# R7FA4C1BD register map
Vendor: Renesas Electronics Corporation; Series: RA4; File version: 1.10.00
CPU: CM33 r0p4, little endian, MPU, FPU, VTOR, 4 interrupt priority bits, 96 interrupts
Registers are 32-bit, read-write, reset 0x0 unless marked. A register's access mark holds for its fields unless they carry their own. Offsets are from the block's base; [hi:lo] are bit positions; <NAME> marks a mode.

## IIC0WU — IIC0 Wake-up Unit
Base 0x4009F014
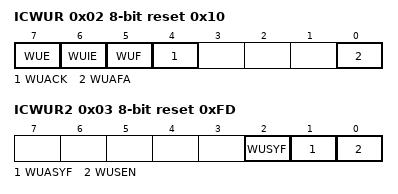
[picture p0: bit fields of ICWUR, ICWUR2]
0x02 ICWUR 8-bit reset 0x10 — I2C Bus Wakeup Unit Register
  [7] WUE — Wakeup Function Enable
    0=Disable wakeup function; 1=Enable wakeup function
  [6] WUIE — Wakeup Interrupt Request Enable
    0=Disable wakeup interrupt request (IIC0_WUI); 1=Enable wakeup interrupt request (IIC0_WUI)
  [5] WUF — Wakeup Event Occurrence Flag
    0=Slave address not matching during wakeup; 1=Slave address matching during wakeup
  [4] WUACK — ACK Bit for Wakeup Mode
  [0] WUAFA — Wakeup Analog Filter Additional Selection
    0=Do not add the wakeup analog filter; 1=Add the wakeup analog filter
0x03 ICWUR2 8-bit reset 0xFD — I2C Bus Wakeup Unit Register 2
  [2] WUSYF ro — Wakeup Function Synchronous Operation Status Flag
    0=IIC asynchronous circuit enable condition; 1=IIC synchronous circuit enable condition
  [1] WUASYF ro — Wakeup Function Asynchronous Operation Status Flag
    0=IIC synchronous circuit enable condition; 1=IIC asynchronous circuit enable condition
  [0] WUSEN — Wakeup Function Synchronous Enable
    0=IIC asynchronous circuit enable; 1=IIC synchronous circuit enable

## CRC — Cyclic Redundancy Check Calculator
Base 0x40108000
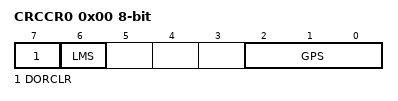
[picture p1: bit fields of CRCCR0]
0x00 CRCCR0 8-bit — CRC Control Register 0
  [7] DORCLR wo — CRCDOR/CRCDOR_HA/CRCDOR_BY Register Clear
    0=No effect; 1=Clear the CRCDOR/CRCDOR_HA/CRCDOR_BY register
  [6] LMS — CRC Calculation Switching
    0=Generate CRC code for LSB-first communication; 1=Generate CRC code for MSB-first communication
  [2:0] GPS — CRC Generating Polynomial Switching
    1=8-bit CRC-8 (X8 + X2 + X + 1); 2=16-bit CRC-16 (X16 + X15 + X2 + 1); 3=16-bit CRC-CCITT (X16 + X12 + X5 + 1); 4=32-bit CRC-32 (X32 + X26 + X23 + X22 + X16 + X12 + X11 +X10 + X8 + X7 + X5 + X4 + X2 + X + 1); 5=32-bit CRC-32C (X32 + X28 + X27 + X26 + X25 + X23 + X22 + X20 + X19 + X18 + X14 + X13 + X11 + X10 + X9 + X8 + X6 + 1); other=Others (No calculation is executed)
0x04 CRCDIR — CRC Data Input Register
0x04 CRCDIR_BY 8-bit (alternate view of CRCDIR) — CRC Data Input Register
0x08 CRCDOR — CRC Data Output Register
0x08 CRCDOR_HA 16-bit (alternate view of CRCDOR) — CRC Data Output Register
0x08 CRCDOR_BY 8-bit (alternate view of CRCDOR) — CRC Data Output Register

## DOC_B — Data Operation Circuit
Base 0x40109000
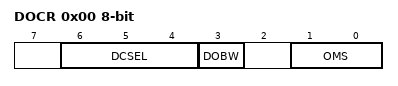
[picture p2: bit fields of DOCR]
0x00 DOCR 8-bit — DOC Control Register
  [6:4] DCSEL — Detection Condition Select
    0=Mismatch (DODSR0 ≠ DODIR); 1=Match (DODSR0 = DODIR); 2=Lower (DODSR0 > DODIR); 3=Upper (DODSR0 < DODIR); 4=Inside window (DODSR0 < DODIR < DODSR1); 5=Outside window (DODIR < DODSR0, DODSR1 < DODIR); other=Others (Setting prohibited)
  [3] DOBW — Data Operation Bit Width Select
    0=16-bit; 1=32-bit
  [1:0] OMS — Operating Mode Select
    0=Data comparison mode; 1=Data addition mode; 2=Data subtraction mode; 3=Setting prohibited
0x04 DOSR 8-bit ro — DOC Flag Status Register
  [0] DOPCF — Data Operation Circuit Flag
0x08 DOSCR 8-bit wo — DOC Flag Status Clear Register
  [0] DOPCFCL — DOPCF Clear
    0=Maintains the DOPCF flag state; 1=Clears the DOPCF flag
0x0C DODIR — DOC Data Input Register
0x10 DODSR0 — DOC Data Setting Register 0
0x14 DODSR1 — DOC Data Setting Register 1

## ECCMB
Base 0x4012F000
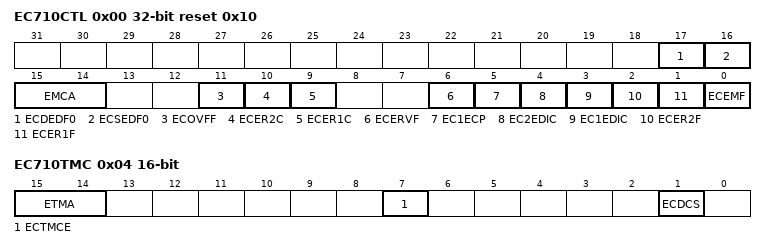
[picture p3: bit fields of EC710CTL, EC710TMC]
0x00 EC710CTL reset 0x10 — ECC Control Register
  [17] ECDEDF0 ro — 2-bit ECC Error Address Detection Flag
    0=2-bit error has not occurred after reset or clearing ECER2F bit; 1=2-bit error has occurred and the address was captured
  [16] ECSEDF0 ro — 1-bit ECC Error Address Detection Flag
    0=1-bit error has not occurred after reset or clearing ECER1F bit; 1=1-bit error has occurred and the address was captured
  [15:14] EMCA — ECC Error Detection Enable Access Control
    1=Can write ECC Error Detection Control (ECERVF) bit; other=Others (Cannot write ECERVF bit)
  [11] ECOVFF ro — ECC Overflow Detection Flag
    0=No clear flag; 1=Clear flag
  [10] ECER2C — 2-bit ECC Error Detection Flag Clear
    0=No clear flag; 1=Clear 2-bit ECC error detection flag
  [9] ECER1C — Accumulating ECC Error Detection and Correction Flag Clear
    0=No clear flag; 1=Clear accumulating ECC error detection and correction flag
  [6] ECERVF — ECC Error Detection Enable
    0=Disable error detection; 1=Enable error detection
  [5] EC1ECP — 1-bit ECC Error Correction Permission
    0=Enable error correction at 1-bit error detection; 1=Disable error correction at 1-bit error detection
  [4] EC2EDIC — 2-bit ECC Error Detection Interrupt Control
    0=Disable 2-bit error detection interrupt request; 1=Enable 2-bit error detection interrupt request
  [3] EC1EDIC — 1-bit ECC Error Detection Interrupt Control
    0=Disable 1-bit error detection interrupt request; 1=Enable 1-bit error detection interrupt request
  [2] ECER2F ro — 2-bit ECC Error Detection Flag
    0=After clearing this bit, 2-bit error has not detected; 1=2-bit error has detected
  [1] ECER1F ro — 1-bit ECC Error Detection and Correction Flag
    0=After clearing this bit, 1-bit error correction has not detected and corrected; 1=1-bit error has detected and corrected
  [0] ECEMF ro — ECC Error Message Flag
    0=There is no bit error in the present RAM output data; 1=There is a bit error in the present RAM output data
0x04 EC710TMC 16-bit — ECC Test Mode Control Register
  [15:14] ETMA — ECC Test Mode Bit Access Control
  [7] ECTMCE — ECC Test Mode Control Enable
    0=The access to test mode register and bit is disabled; 1=The access to test mode register and bit is enabled
  [1] ECDCS — ECC Decode Input Select
    0=Input lower 32 bits of RAM output data to data area of decode circuit; 1=Input ECEDB31-0 in EC710TED register to data area of decode circuit
0x0C EC710TED — ECC Test Substitute Data Register
  [31:0] ECEDB — ECC Test Substitute Data
0x10 EC710EAD0 ro — ECC Error Address Register
  [9:0] ECEAD — ECC Error Address

## GPT_OPS — Output Phase Switching Controller
Base 0x40169A00
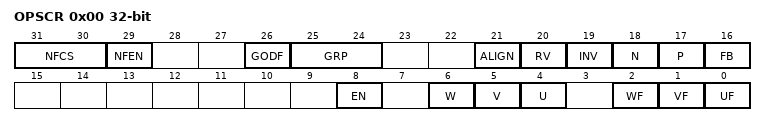
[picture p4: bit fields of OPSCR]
0x00 OPSCR — Output Phase Switching Control Register
  [31:30] NFCS — External Input Noise Filter Clock Selection
    0=PCLKD/1; 1=PCLKD/4; 2=PCLKD/16; 3=PCLKD/64
  [29] NFEN — External Input Noise Filter Enable
    0=Do not use a noise filter on the external input; 1=Use a noise filter on the external input
  [26] GODF — Group Output Disable Function
    0=This bit function is ignored; 1=Group disable clears the OPSCR.EN bit
  [25:24] GRP — Output Disabled Source Selection
  [21] ALIGN — Input Phase Alignment
    0=Input phase aligned to PCLKD; 1=Input phase aligned to the falling edge of PWM
  [20] RV — Output Phase Rotation Direction Reversal Control
    0=Positive rotation; 1=Reverse rotation
  [19] INV — Output Phase Invert Control
    0=Positive logic (active-high) output; 1=Negative logic (active-low) output
  [18] N — Negative-Phase Output (N) Control
    0=Level signal output; 1=PWM signal output
  [17] P — Positive-Phase Output (P) Control
    0=Level signal output; 1=PWM signal output
  [16] FB — External Feedback Signal Enable
    0=Select the external input; 1=Select the soft setting (OPSCR.UF, VF, WF)
  [8] EN — Output Phase Enable
    0=Do not output (Hi-Z external pin); 1=Output
  [6] W ro — Input W-Phase Monitor
  [5] V ro — Input V-Phase Monitor
  [4] U ro — Input U-Phase Monitor
  [2] WF
  [1] VF
  [0] UF

## FLCN — Flash I/O Registers
Base 0x407EC000
0x90 DFLCTL 8-bit — Data Flash Control Register
  [0] DFLEN — Data Flash Access Enable
    0=Access to the data flash is disabled; 1=Access to the data flash is enabled
0x228 TSCDR 16-bit ro reset not defined — Temperature Sensor Calibration Data Register
0x22A TSCDRR 16-bit ro — Temperature Sensor Calibration Data Register (Room Temperature)
0x350 TSCDRL 16-bit ro — Temperature Sensor Calibration Data Register (Low Temperature)
0x3FC4 FLDWAITR 8-bit — Memory Wait Cycle Control Register for Data Flash
  [0] FLDWAIT1 — Memory Wait Cycle Select for Data Flash
    0=One wait access (default); 1=Two wait accesses
0x3FC8 PFBER 8-bit — Prefetch Buffer Enable Register
  [0] PFBE — Prefetch Buffer Enable bit
    0=Prefetch buffer is disabled; 1=Prefetch buffer is enabled

## CPU_OCD — OCD Function
Base 0x80000000
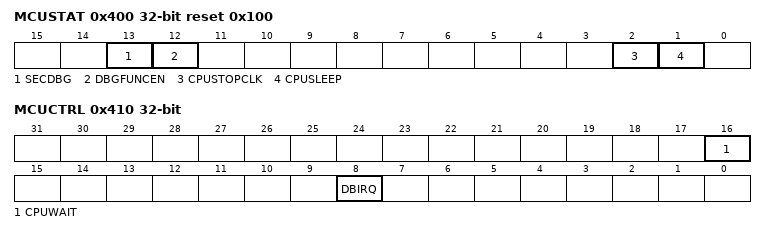
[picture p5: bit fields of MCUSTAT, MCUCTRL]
0x400 MCUSTAT ro reset 0x100 (reset mask 0xFFFFCFF9) — MCU Status Register
  [13] SECDBG — Secure Debug status
    0=Secure Debug is not available; 1=Secure Debug is available
  [12] DBGFUNCEN — Debugger status
    0=Debugger connection is not available; 1=Debugger function is enabled
  [2] CPUSTOPCLK — CPU clock status
    0=CPU clock is not stopped; 1=CPU clock is stopped
  [1] CPUSLEEP — Sleep mode status
    0=CPU is not in Sleep mode; 1=CPU in Sleep mode
0x410 MCUCTRL — MCU Control Register
  [16] CPUWAIT — CPU Wait Setting
    0=Clear CPUWAIT to low; 1=Set CPUWAIT to high
  [8] DBIRQ — Debug Interrupt Request
    0=Debug interrupt not requested; 1=Debug interrupt requested
